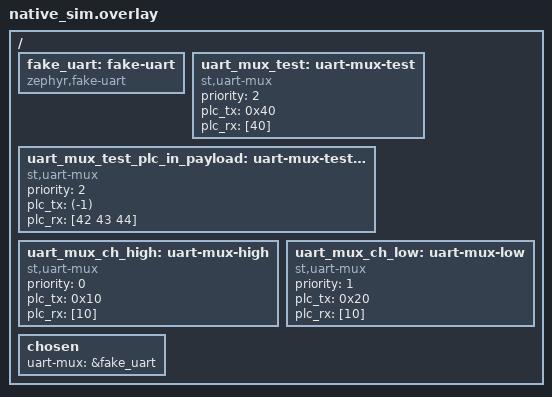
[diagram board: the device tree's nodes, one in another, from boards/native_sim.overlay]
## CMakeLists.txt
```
# SPDX-License-Identifier: Apache-2.0

cmake_minimum_required(VERSION 3.20.0)

# Add the parent directory to the DTS search path
# CMAKE_CURRENT_SOURCE_DIR is the folder containing this CMakeLists.txt
set(DTS_ROOT ${CMAKE_CURRENT_SOURCE_DIR}/../..)

find_package(Zephyr REQUIRED HINTS $ENV{ZEPHYR_BASE})
project(rcp_ble_ot)

zephyr_include_directories(${CMAKE_CURRENT_LIST_DIR}/../../src)

target_sources(app PRIVATE
  ../../src/uart_mux.c
  src/test_rx.c
  src/test_tx.c
  src/fake_uart.c
)
```

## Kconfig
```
source "Kconfig.zephyr"

source "rcp_ble_ot/src/Kconfig.uart_mux"

config UART_FAKE_CUSTOM
    bool "Fake UART Driver"
    default y
    # This is the "Magic" part that fixes your error:
    select SERIAL_HAS_DRIVER
    select SERIAL_SUPPORT_ASYNC
```

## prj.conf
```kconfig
CONFIG_ZTEST=y

# Serial / UART
CONFIG_SERIAL=y
CONFIG_UART_ASYNC_API=y

# Your mux
CONFIG_UART_MUX=y

# Memory / stacks
CONFIG_MAIN_STACK_SIZE=4096
CONFIG_SYSTEM_WORKQUEUE_STACK_SIZE=2048

# Logging off initially (reduce noise)
CONFIG_TEST_LOGGING_DEFAULTS=n
CONFIG_LOG=n

# Debug
CONFIG_COMPILER_SAVE_TEMPS=y
CONFIG_NO_OPTIMIZATIONS=y
CONFIG_DEBUG=y
```

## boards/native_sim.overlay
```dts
/ {
	fake_uart: fake-uart {
		compatible = "zephyr,fake-uart";
		status = "okay";
	};

	uart_mux_test: uart-mux-test {
		compatible = "st,uart-mux";
		status = "okay";
		priority = <2>;

		plc_tx = <0x40>;
		plc_rx = [40];
	};

	uart_mux_test_plc_in_payload: uart-mux-test-plc-in-payload {
		compatible = "st,uart-mux";
		status = "okay";
		priority = <2>;

		plc_tx = <(-1)>;
		plc_rx = [42 43 44];
	};

	uart_mux_ch_high: uart-mux-high {
		compatible = "st,uart-mux";
		priority = <0>; /* higher */
		plc_tx = <0x10>;
		plc_rx = [10];
		status = "okay";
	};

	uart_mux_ch_low: uart-mux-low {
		compatible = "st,uart-mux";
		priority = <1>; /* lower */
		plc_tx = <0x20>;
		plc_rx = [10];
		status = "okay";
	};

	chosen {
		uart-mux = &fake_uart;
	};
};
```

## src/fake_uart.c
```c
/*
 * Fake UART driver for uart_mux unit tests
 *
 * This driver implements a minimal UART async API sufficient to:
 *  - accept uart_tx() calls
 *  - immediately complete TX with UART_TX_DONE
 *  - optionally inject UART_TX_ABORTED
 *  - inject RX data as UART_RX_RDY events
 *
 * It is NOT a real UART driver.
 * It is intentionally synchronous and simplified to:
 *  - make tests deterministic
 *  - avoid timing dependencies
 *  - avoid hardware
 *
 * Design goals:
 *  - correctness over realism
 *  - bounded memory usage
 *  - stress-safe (no buffer overruns)
 */

#include <zephyr/device.h>
#include <zephyr/drivers/uart.h>
#include <zephyr/kernel.h>
#include <zephyr/sys/util.h>
#include <string.h>

#define FAKE_UART DEVICE_DT_GET(DT_NODELABEL(fake_uart))

#define DT_DRV_COMPAT zephyr_fake_uart

/* -------------------------------------------------------------------------- */
/* Configuration                                                              */
/* -------------------------------------------------------------------------- */

/*
 * Maximum number of TX operations whose buffers/lengths are recorded
 * for inspection by tests.
 *
 * After this limit, TX operations are still counted, but buffers
 * are no longer stored to avoid memory corruption during stress tests.
 */
#define FAKE_UART_MAX_TX_CAPTURE 16

/* -------------------------------------------------------------------------- */
/* Fake UART state                                                             */
/* -------------------------------------------------------------------------- */

/*
 * Registered UART callback and user data.
 * These are set by uart_callback_set() and used to emit events.
 */
static uart_callback_t fake_cb;
static void *fake_cb_data;

/*
 * TX capture state.
 *
 * tx_count:
 *   Total number of uart_tx() calls received since last reset.
 *
 * tx_bufs / tx_lens:
 *   Pointers and lengths of the first FAKE_UART_MAX_TX_CAPTURE
 *   transmissions. Used by tests to inspect framing behavior.
 *
 * IMPORTANT:
 *   These arrays are bounded. They never overflow.
 */
static const uint8_t *tx_bufs[FAKE_UART_MAX_TX_CAPTURE];
static size_t tx_lens[FAKE_UART_MAX_TX_CAPTURE];
static int tx_count;

/*
 * RX enable state.
 *
 * rx_enabled:
 *   True after uart_rx_enable() has been called.
 *
 * rx_timeout_ms:
 *   Stored for completeness, but not used (RX is synchronous).
 */
static bool rx_enabled;
static int32_t rx_timeout_ms;

/* -------------------------------------------------------------------------- */
/* Fake UART driver API                                                        */
/* -------------------------------------------------------------------------- */

/*
 * Set UART async callback.
 *
 * Stores callback and user data for later use when generating
 * UART events (TX_DONE, RX_RDY, TX_ABORTED).
 */
static int fake_uart_callback_set(const struct device *dev,
				  uart_callback_t cb,
				  void *user_data)
{
	ARG_UNUSED(dev);

	fake_cb = cb;
	fake_cb_data = user_data;
	return 0;
}

/*
 * Fake async TX.
 *
 * Behavior:
 *  - Record buffer pointer and length (bounded)
 *  - Increment total TX count
 *  - Immediately emit UART_TX_DONE
 *
 * This mimics a UART that completes TX instantly.
 */
static int fake_uart_tx(const struct device *dev,
			const uint8_t *buf,
			size_t len,
			int32_t timeout)
{
	ARG_UNUSED(dev);
	ARG_UNUSED(timeout);

	/* Capture TX metadata for tests (bounded) */
	if (tx_count < FAKE_UART_MAX_TX_CAPTURE) {
		tx_bufs[tx_count] = buf;
		tx_lens[tx_count] = len;
	}

	tx_count++;

	/* Emit TX_DONE immediately */
	if (fake_cb) {
		struct uart_event evt = {
			.type = UART_TX_DONE,
			.data.tx.buf = buf,
			.data.tx.len = len,
		};

		fake_cb(dev, &evt, fake_cb_data);
	}

	return 0;
}

/*
 * Fake RX enable.
 *
 * Enables RX event delivery. No buffers are managed here;
 * RX data is injected explicitly by test helpers.
 */
static int fake_uart_rx_enable(const struct device *dev,
			       uint8_t *buf,
			       size_t len,
			       int32_t timeout)
{
	ARG_UNUSED(dev);
	ARG_UNUSED(buf);
	ARG_UNUSED(len);

	rx_enabled = true;
	rx_timeout_ms = timeout;
	return 0;
}

/*
 * Fake RX disable.
 */
static int fake_uart_rx_disable(const struct device *dev)
{
	ARG_UNUSED(dev);

	rx_enabled = false;
	return 0;
}

/* -------------------------------------------------------------------------- */
/* UART driver API table                                                       */
/* -------------------------------------------------------------------------- */

static const struct uart_driver_api fake_uart_api = {
	.callback_set = fake_uart_callback_set,
	.tx = fake_uart_tx,
	.rx_enable = fake_uart_rx_enable,
	.rx_disable = fake_uart_rx_disable,
};

/* -------------------------------------------------------------------------- */
/* Device instantiation                                                        */
/* -------------------------------------------------------------------------- */

DEVICE_DT_DEFINE(DT_NODELABEL(fake_uart),
		 NULL,
		 NULL,
		 NULL,
		 NULL,
		 POST_KERNEL,
		 CONFIG_KERNEL_INIT_PRIORITY_DEVICE,
		 &fake_uart_api);

/* -------------------------------------------------------------------------- */
/* Test helper functions (not part of UART API)                                */
/* -------------------------------------------------------------------------- */

/*
 * Reset TX capture state.
 *
 * Used at the beginning of tests to ensure a clean slate.
 */
void fake_uart_reset_tx(void)
{
	tx_count = 0;
	memset(tx_bufs, 0, sizeof(tx_bufs));
	memset(tx_lens, 0, sizeof(tx_lens));
}

/*
 * Get total number of uart_tx() calls observed.
 *
 * This number may exceed FAKE_UART_MAX_TX_CAPTURE.
 */
int fake_uart_get_tx_count(void)
{
	return tx_count;
}

/*
 * Get pointer to TX buffer for a captured TX index.
 *
 * Returns NULL if index is out of capture range.
 */
const uint8_t *fake_uart_get_tx_buf(int idx)
{
	if (idx < 0 || idx >= FAKE_UART_MAX_TX_CAPTURE) {
		return NULL;
	}

	return tx_bufs[idx];
}

/*
 * Get TX length for a captured TX index.
 *
 * Returns 0 if index is out of capture range.
 */
size_t fake_uart_get_tx_len(int idx)
{
	if (idx < 0 || idx >= FAKE_UART_MAX_TX_CAPTURE) {
		return 0;
	}

	return tx_lens[idx];
}

/*
 * Inject an RX frame into the fake UART.
 *
 * This generates a UART_RX_RDY event if RX is enabled.
 * Data is delivered exactly as provided.
 */
void fake_uart_inject_rx(const uint8_t *data, size_t len)
{
	if (!rx_enabled || !fake_cb) {
		return;
	}

	struct uart_event evt = {
		.type = UART_RX_RDY,
		.data.rx.buf = (uint8_t *) data,
		.data.rx.len = len,
	};

	fake_cb(FAKE_UART, &evt, fake_cb_data);
}

/*
 * Inject a TX_ABORTED event.
 *
 * Used to test recovery paths in uart_mux.
 */
void fake_uart_inject_tx_abort(void)
{
	if (!fake_cb) {
		return;
	}

	struct uart_event evt = {
		.type = UART_TX_ABORTED,
	};

	fake_cb(FAKE_UART, &evt, fake_cb_data);
}
```

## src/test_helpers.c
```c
#include <stdlib.h>
#include <stdint.h>
#include <string.h>
#include "test_helpers.h"

extern void fake_uart_inject_rx(const uint8_t *data, size_t len);

static uint16_t crc16_ccitt_update(uint16_t crc, uint8_t data)
{
	crc ^= (uint16_t)data << 8;

	for (int i = 0; i < 8; i++) {
		if (crc & 0x8000) {
			crc = (crc << 1) ^ 0x1021;
		} else {
			crc <<= 1;
		}
	}

	return crc;
}

void inject_garbage(size_t len)
{
	uint8_t buf[32];

	if (len > sizeof(buf)) {
		len = sizeof(buf);
	}

	for (size_t i = 0; i < len; i++) {
		buf[i] = rand() & 0xFF;
	}

	fake_uart_inject_rx(buf, len);
}

void inject_valid_frame(uint8_t plc, const uint8_t *payload, size_t len)
{
	uint8_t frame[64];
	size_t pos = 0;

	frame[pos++] = 0xC0;
	frame[pos++] = 0x02;
	frame[pos++] = len & 0xFF;
	frame[pos++] = len >> 8;
	frame[pos++] = plc;

	memcpy(&frame[pos], payload, len);
	pos += len;

	patch_crc_to_frame(frame, pos + 2);
	pos = pos + 2;

	fake_uart_inject_rx(frame, pos);
}

void patch_crc_to_frame(uint8_t* frame, uint16_t len)
{
	uint16_t crc = 0xFFFF;
	for (size_t i = 0; i < (len - 2); i++) {
		crc = crc16_ccitt_update(crc, frame[i]);
	}
	crc ^= 0xFFFF;
	frame[len - 2] = crc & 0xFF;
	frame[len - 1] = crc >> 8;
}
```

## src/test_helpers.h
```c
#pragma once
#include <stddef.h>
#include <stdint.h>

void inject_garbage(size_t len);
void inject_valid_frame(uint8_t plc, const uint8_t *payload, size_t len);
void patch_crc_to_frame(uint8_t* frame, uint16_t len);
```

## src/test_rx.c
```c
#include <zephyr/ztest.h>
#include <zephyr/drivers/uart.h>
#include "uart_mux.h"
#include "test_helpers.h"

/* captured RX */
static uint8_t rx_buf[64];
static size_t rx_len;

static void test_uart_cb(const struct device *dev,
			 struct uart_event *evt,
			 void *user_data)
{
	ARG_UNUSED(dev);
	ARG_UNUSED(user_data);

	if (evt->type == UART_RX_RDY) {
		memcpy(rx_buf, evt->data.rx.buf, evt->data.rx.len);
		rx_len = evt->data.rx.len;
	}
}
extern void fake_uart_inject_rx(const uint8_t *data, size_t len);

ZTEST(uart_mux_rx, test_valid_frame)
{
	uint8_t frame[] = {
		0xC0,       /* FI */
		0x02,       /* FF */
		0x00, /* LEN LSB, filled later */
		0x00,   /* LEN MSB, filled later */
		0x40,       /* PLC */
		0x41, 0x01, 0x02, /* payload */
		0x00, 0x00  /* CRC (filled below) */
	};

	const struct device *vdev;
	uint32_t frames_ok;
	struct uart_mux_rx_stats stats;
	uint8_t plc_is_first_bye_of_payload = 0;
	uint16_t payload_offset = plc_is_first_bye_of_payload ? 4 : 5;
	uint16_t length_in_header = sizeof(frame) - 5 - 2;

	uart_mux_get_rx_stats(&stats);
	frames_ok = stats.frames_ok;

	rx_len = 0;

	/* Virtual UART device from DTS */
	vdev = DEVICE_DT_GET(DT_NODELABEL(uart_mux_test));
	zassert_true(device_is_ready(vdev), NULL);

	uart_callback_set(vdev, test_uart_cb, NULL);
	uart_rx_enable(vdev, NULL, 0, SYS_FOREVER_MS);
	uint8_t *payload;
	uint16_t len;

	payload = frame + payload_offset;
	len =  sizeof(frame) - payload_offset - 2;

	frame[2] = length_in_header & 0xFF; /* LEN LSB */
	frame[3] = length_in_header >> 8;   /* LEN MSB */

	patch_crc_to_frame(frame, sizeof(frame));
	fake_uart_inject_rx(frame, sizeof(frame));

	zassert_equal(rx_len, len, NULL);
	zassert_mem_equal(rx_buf, payload, len, NULL);

	uart_mux_get_rx_stats(&stats);
	zassert_equal(stats.frames_ok, frames_ok + 1, NULL);
}

ZTEST(uart_mux_rx, test_valid_frame2)
{
	uint8_t frame[] = {
		0xC0,       /* FI */
		0x02,       /* FF */
		0x00, /* LEN LSB, filled later */
		0x00,   /* LEN MSB, filled later */
		0x42,       /* PLC */
		0x01, 0x02, 0x03, /* payload */
		0x00, 0x00  /* CRC (filled below) */
	};

	const struct device *vdev;
	uint32_t frames_ok;
	struct uart_mux_rx_stats stats;
	uint8_t plc_is_first_bye_of_payload = 1;
	uint16_t payload_offset = plc_is_first_bye_of_payload ? 4 : 5;
	uint16_t length_in_header = sizeof(frame) - 5 - 2;

	uart_mux_get_rx_stats(&stats);
	frames_ok = stats.frames_ok;

	rx_len = 0;

	/* Virtual UART device from DTS */
	vdev = DEVICE_DT_GET(DT_NODELABEL(uart_mux_test_plc_in_payload));
	zassert_true(device_is_ready(vdev), NULL);

	uart_callback_set(vdev, test_uart_cb, NULL);
	uart_rx_enable(vdev, NULL, 0, SYS_FOREVER_MS);
	uint8_t *payload;
	uint16_t len;

	payload = frame + payload_offset;
	len =  sizeof(frame) - payload_offset - 2;

	frame[2] = length_in_header & 0xFF; /* LEN LSB */
	frame[3] = length_in_header >> 8;   /* LEN MSB */

	patch_crc_to_frame(frame, sizeof(frame));
	fake_uart_inject_rx(frame, sizeof(frame));

	zassert_equal(rx_len, len, NULL);
	zassert_mem_equal(rx_buf, payload, len, NULL);

	uart_mux_get_rx_stats(&stats);
	zassert_equal(stats.frames_ok, frames_ok + 1, NULL);
}

ZTEST_SUITE(uart_mux_rx, NULL, NULL, NULL, NULL, NULL);
```

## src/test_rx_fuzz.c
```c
#include <zephyr/ztest.h>
#include "uart_mux.h"
#include "test_helpers.h"

static size_t rx_count;

static void cb(const struct device *dev,
	       struct uart_event *evt,
	       void *ud)
{
	if (evt->type == UART_RX_RDY) {
		rx_count++;
	}
}

ZTEST(uart_mux_rx, test_rx_fuzz_resync)
{
	const struct device *dev;

	dev = DEVICE_DT_GET(DT_NODELABEL(uart_mux_ch_high));
	zassert_true(device_is_ready(dev), NULL);

	uart_callback_set(dev, cb, NULL);
	uart_rx_enable(dev, NULL, 0, SYS_FOREVER_MS);

	rx_count = 0;

	/* Garbage storm */
	for (int i = 0; i < 50; i++) {
		inject_garbage(7);
	}

	zassert_equal(rx_count, 0, "Garbage produced RX!");

	/* Valid frame must recover */
	uint8_t p[] = { 0xAA };
	inject_valid_frame(0x10, p, sizeof(p));

	zassert_equal(rx_count, 1, "Did not resync on valid frame");
}
```

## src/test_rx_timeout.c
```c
#include <zephyr/ztest.h>
#include <zephyr/drivers/uart.h>
#include "test_helpers.h"

extern void fake_uart_inject_rx(const uint8_t *data, size_t len);

static void cb(const struct device *dev,
			 struct uart_event *evt,
			 void *user_data)
{
	size_t *rx_count = user_data;

	if (evt->type == UART_RX_RDY) {
		(*rx_count)++;
	}
}

ZTEST(uart_mux_rx, test_rx_timeout_resets_state)
{
	const struct device *dev;
	size_t rx_count = 0;

	dev = DEVICE_DT_GET(DT_NODELABEL(uart_mux_ch_high));
	zassert_true(device_is_ready(dev), NULL);

	uart_callback_set(dev, cb, &rx_count);

	uart_rx_enable(dev, NULL, 0, SYS_FOREVER_MS);

	/* Send incomplete header */
	uint8_t partial[] = { 0xC0, 0x02 };
	fake_uart_inject_rx(partial, sizeof(partial));

	/* Wait past timeout */
	k_sleep(K_MSEC(CONFIG_UART_MUX_RX_TIMEOUT_MS + 10));

	/* Now valid frame must be accepted */
	uint8_t p[] = { 0x55 };
	inject_valid_frame(0x10, p, sizeof(p));

	zassert_equal(rx_count, 1, NULL);
}
```

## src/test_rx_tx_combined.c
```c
#include <zephyr/ztest.h>
#include <zephyr/drivers/uart.h>
#include "uart_mux.h"
#include "test_helpers.h"

extern void fake_uart_inject_rx(const uint8_t *data, size_t len);
extern void fake_uart_reset_tx(void);

static uint8_t rx_buf[16];
static size_t rx_len;

static void cb(const struct device *dev,
	       struct uart_event *evt,
	       void *ud)
{
	if (evt->type == UART_RX_RDY) {
		memcpy(rx_buf, evt->data.rx.buf, evt->data.rx.len);
		rx_len = evt->data.rx.len;
	}
}

ZTEST(uart_mux_combined, test_rx_tx_parallel)
{
	const struct device *dev;

	dev = DEVICE_DT_GET(DT_NODELABEL(uart_mux_ch_high));
	zassert_true(device_is_ready(dev), NULL);

	uart_callback_set(dev, cb, NULL);
	uart_rx_enable(dev, NULL, 0, SYS_FOREVER_MS);

	fake_uart_reset_tx();
	rx_len = 0;

	uint8_t payload[] = { 0x55 };

	/* TX */
	uart_tx(dev, payload, sizeof(payload), SYS_FOREVER_MS);

	/* RX frame */
	uint8_t frame[] = {
		0xC0, 0x02, 0x01, 0x00, 0x10,
		0x55, 0x00, 0x00
	};
	patch_crc_to_frame(frame, sizeof(frame));
	fake_uart_inject_rx(frame, sizeof(frame));

	zassert_equal(rx_len, 1, NULL);
	zassert_equal(rx_buf[0], 0x55, NULL);
}
ZTEST_SUITE(uart_mux_combined, NULL, NULL, NULL, NULL, NULL);
```

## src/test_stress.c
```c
#include <zephyr/ztest.h>
#include <zephyr/drivers/uart.h>
#include "test_helpers.h"

extern void fake_uart_reset_tx(void);

static void cb(const struct device *dev,
			 struct uart_event *evt,
			 void *user_data)
{
	size_t *rx_count = user_data;

	if (evt->type == UART_RX_RDY) {
		(*rx_count)++;
	}
}

ZTEST(uart_mux_stress, test_rx_tx_stress)
{
	const struct device *dev;
	size_t rx_count;
	uint8_t tx_buf;
	uint8_t rx_buf;

	dev = DEVICE_DT_GET(DT_NODELABEL(uart_mux_ch_high));
	zassert_true(device_is_ready(dev), NULL);

	rx_count = 0;
	uart_callback_set(dev, cb, &rx_count);

	uart_rx_enable(dev, NULL, 0, SYS_FOREVER_MS);

	for (int i = 0; i < 100; i++) {
		tx_buf = (uint8_t)i;
		rx_buf = (uint8_t)i;

		/* TX */
		uart_tx(dev, &tx_buf, 1, SYS_FOREVER_MS);

		/* RX */
		inject_valid_frame(0x10, &rx_buf, 1);
	}

	zassert_equal(rx_count, 100, NULL);
}
ZTEST_SUITE(uart_mux_stress,
	    NULL,  /* suite setup */
	    NULL,  /* suite teardown */
	    NULL,  /* test setup */
	    NULL,  /* test teardown */
	    NULL); /* fixture */
```

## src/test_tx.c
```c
#include <zephyr/ztest.h>
#include <zephyr/drivers/uart.h>
#include "uart_mux.h"

/* fake uart helpers */
extern void fake_uart_reset_tx(void);
extern int fake_uart_get_tx_count(void);
extern const uint8_t *fake_uart_get_tx_buf(int idx);
extern size_t fake_uart_get_tx_len(int idx);

ZTEST(uart_mux_tx, test_single_frame_tx)
{
	const struct device *vdev;

	vdev = DEVICE_DT_GET(DT_NODELABEL(uart_mux_test));
	zassert_true(device_is_ready(vdev), NULL);

	fake_uart_reset_tx();

	uint8_t payload[] = { 0x10, 0x20, 0x30 };

	int ret = uart_tx(vdev, payload, sizeof(payload), SYS_FOREVER_MS);
	zassert_equal(ret, 0, NULL);

	/* TX is synchronous in fake uart */
	zassert_equal(fake_uart_get_tx_count(), 3, NULL);

	/* 0: header */
	zassert_equal(fake_uart_get_tx_len(0), 5, NULL);

	/* 1: payload */
	zassert_equal(fake_uart_get_tx_len(1), sizeof(payload), NULL);
	zassert_mem_equal(fake_uart_get_tx_buf(1), payload, sizeof(payload), NULL);

	/* 2: CRC */
	zassert_equal(fake_uart_get_tx_len(2), 2, NULL);
}

ZTEST_SUITE(uart_mux_tx, NULL, NULL, NULL, NULL, NULL);
```

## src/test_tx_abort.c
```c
#include <zephyr/ztest.h>
#include <zephyr/drivers/uart.h>

extern void fake_uart_reset_tx(void);
extern void fake_uart_inject_tx_abort(void);
extern int fake_uart_get_tx_count(void);
ZTEST(uart_mux_tx, test_tx_abort_recovery)
{
	const struct device *dev;

	dev = DEVICE_DT_GET(DT_NODELABEL(uart_mux_ch_high));
	zassert_true(device_is_ready(dev), NULL);

	fake_uart_reset_tx();

	uint8_t p[] = { 0xAA };

	uart_tx(dev, p, sizeof(p), SYS_FOREVER_MS);

	/* Abort during header */
	fake_uart_inject_tx_abort();

	/* Retry */
	uart_tx(dev, p, sizeof(p), SYS_FOREVER_MS);

	zassert_true(fake_uart_get_tx_count() >= 3, NULL);
}
```

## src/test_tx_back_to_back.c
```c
#include <zephyr/ztest.h>
#include <zephyr/drivers/uart.h>

extern void fake_uart_reset_tx(void);
extern int fake_uart_get_tx_count(void);

ZTEST(uart_mux_tx, test_tx_back_to_back)
{
	const struct device *dev;

	dev = DEVICE_DT_GET(DT_NODELABEL(uart_mux_ch_high));
	zassert_true(device_is_ready(dev), NULL);

	fake_uart_reset_tx();

	uint8_t p1[] = { 0x01 };
	uint8_t p2[] = { 0x02 };

	uart_tx(dev, p1, sizeof(p1), SYS_FOREVER_MS);
	uart_tx(dev, p2, sizeof(p2), SYS_FOREVER_MS);

	/* Two frames = 6 TX segments */
	zassert_equal(fake_uart_get_tx_count(), 6, NULL);
}
```

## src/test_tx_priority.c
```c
#include <zephyr/ztest.h>
#include <zephyr/drivers/uart.h>

extern void fake_uart_reset_tx(void);
extern int fake_uart_get_tx_count(void);
extern const uint8_t *fake_uart_get_tx_buf(int idx);


ZTEST(uart_mux_tx, test_tx_priority_arbitration)
{
	const struct device *high;
	const struct device *low;

	high = DEVICE_DT_GET(DT_NODELABEL(uart_mux_ch_high));
	low  = DEVICE_DT_GET(DT_NODELABEL(uart_mux_ch_low));

	zassert_true(device_is_ready(high), NULL);
	zassert_true(device_is_ready(low), NULL);

	fake_uart_reset_tx();

	uint8_t p1[] = { 0x01 };
	uint8_t p2[] = { 0x02 };

	/* Enqueue low first */
	uart_tx(low, p2, sizeof(p2), SYS_FOREVER_MS);
	uart_tx(high, p1, sizeof(p1), SYS_FOREVER_MS);

	/* fake UART executes immediately */
	zassert_equal(fake_uart_get_tx_count(), 6, NULL);

	/* First header belongs to high priority channel */
	const uint8_t *hdr = fake_uart_get_tx_buf(0);
	zassert_equal(hdr[4], 0x10, "High priority PLC expected");
}
```
